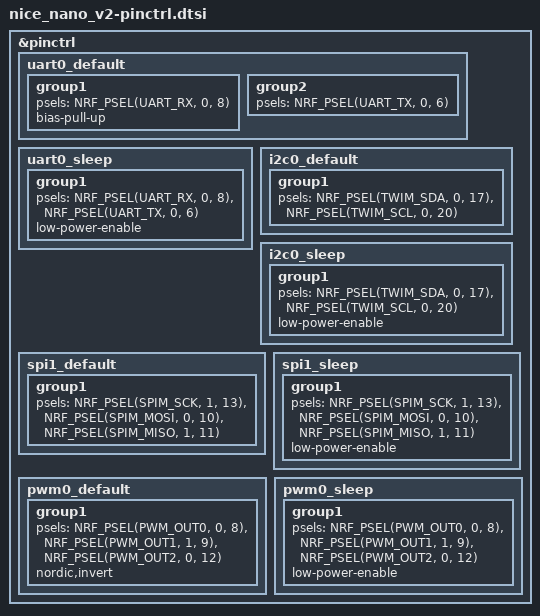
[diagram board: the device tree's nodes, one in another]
&pinctrl {
    uart0_default: uart0_default {
        group1 {
            psels = <NRF_PSEL(UART_RX, 0, 8)>;
            bias-pull-up;
        };
        group2 {
            psels = <NRF_PSEL(UART_TX, 0, 6)>;
        };
    };

    uart0_sleep: uart0_sleep {
        group1 {
            psels = <NRF_PSEL(UART_RX, 0, 8)>,
                    <NRF_PSEL(UART_TX, 0, 6)>;
            low-power-enable;
        };
    };

    i2c0_default: i2c0_default {
        group1 {
            psels = <NRF_PSEL(TWIM_SDA, 0, 17)>,
                    <NRF_PSEL(TWIM_SCL, 0, 20)>;
        };
    };

    i2c0_sleep: i2c0_sleep {
        group1 {
            psels = <NRF_PSEL(TWIM_SDA, 0, 17)>,
                    <NRF_PSEL(TWIM_SCL, 0, 20)>;
            low-power-enable;
        };
    };

    spi1_default: spi1_default {
        group1 {
            psels = <NRF_PSEL(SPIM_SCK, 1, 13)>,
                    <NRF_PSEL(SPIM_MOSI, 0, 10)>,
                    <NRF_PSEL(SPIM_MISO, 1, 11)>;
        };
    };

    spi1_sleep: spi1_sleep {
        group1 {
            psels = <NRF_PSEL(SPIM_SCK, 1, 13)>,
                    <NRF_PSEL(SPIM_MOSI, 0, 10)>,
                    <NRF_PSEL(SPIM_MISO, 1, 11)>;
            low-power-enable;
        };
    };


    /* COPIED FROM NRF9160DONGLE -- MAY NOT WORK */
    pwm0_default: pwm0_default {
        group1 {
            psels = <NRF_PSEL(PWM_OUT0, 0, 8)>,
                    <NRF_PSEL(PWM_OUT1, 1, 9)>,
                    <NRF_PSEL(PWM_OUT2, 0, 12)>;
            nordic,invert;
        };
    };

    pwm0_sleep: pwm0_sleep {
        group1 {
            psels = <NRF_PSEL(PWM_OUT0, 0, 8)>,
                    <NRF_PSEL(PWM_OUT1, 1, 9)>,
                    <NRF_PSEL(PWM_OUT2, 0, 12)>;
            low-power-enable;
        };
    };

};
